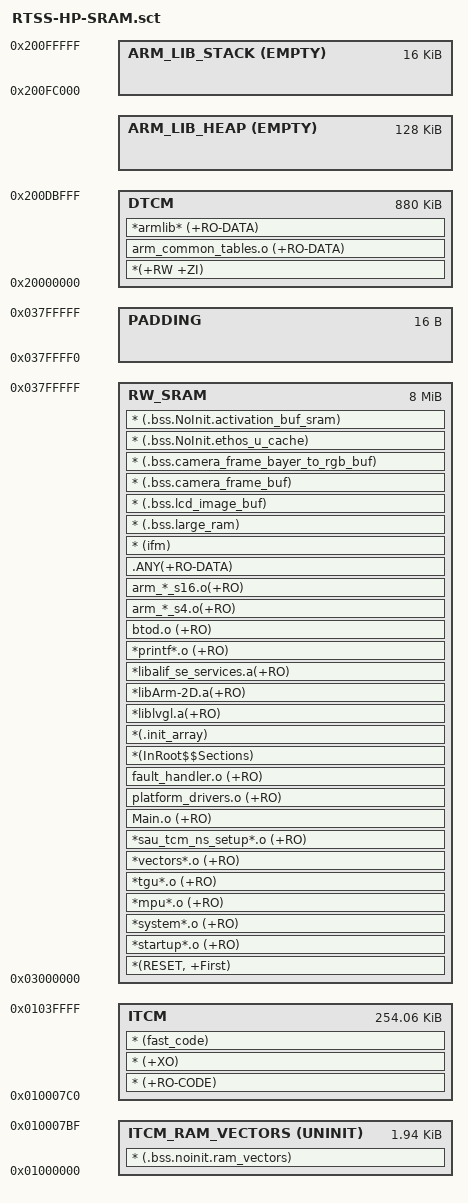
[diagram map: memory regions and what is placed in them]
#! armclang -E --target=arm-arm-none-eabi -mcpu=cortex-m55 -xc
; command above MUST be in first line (no comment above!)

;/* Copyright (C) 2022 Alif Semiconductor - All Rights Reserved.
; * Use, distribution and modification of this code is permitted under the
; * terms stated in the Alif Semiconductor Software License Agreement
; *
; * You should have received a copy of the Alif Semiconductor Software
; * License Agreement with this file. If not, please write to:
; * contact@alifsemi.com, or visit: https://alifsemi.com/license
; *
; */

/*On chip RAM Regions */
#define SRAM_BASE                 0x03000000
#define SRAM_SIZE                 0x00800000		/* 8M */
/* On Chip NVM */
#define MRAM_BASE                 0x80000000
#define MRAM_SIZE                 0x00580000		/* 5.5M */

/*--------------------- ITCM Configuration ----------------------------------*/
/* SRAM2 is mapped as ITCM */
#define ITCM_BASE                 0x01000000
#define ITCM_SIZE                 0x00040000        /* 256K */

/*--------------------- DTCM Configuration ---------------------------*/
/* SRAM3 is mapped as DTCM */
#define DTCM_BASE                 0x20000000
#define DTCM_SIZE                 0x00100000        /* 1M */

#define __VECTORS_SIZE  (496 * 4)
#define __STACK_SIZE    0x00004000
#define __HEAP_SIZE     0x00020000

;----------------------------------------------------------------------------
;   User Stack & Heap boundary definition
;----------------------------------------------------------------------------
#define __STACK_TOP     (DTCM_BASE + DTCM_SIZE)       /* starts at end of RAM */
#define __HEAP_BASE     (AlignExpr(+0, 8))            /* starts after RW_RAM section, 8 byte aligned */

;----------------------------------------------------------------------------
;  Scatter File Definitions definition
;----------------------------------------------------------------------------
#define __RO_BASE       SRAM_BASE
#define __RO_SIZE       SRAM_SIZE

#define __RW_BASE       DTCM_BASE
#define __RW_SIZE      (DTCM_SIZE - __STACK_SIZE - __HEAP_SIZE)


LR_SRAM __RO_BASE __RO_SIZE  {                       ; load region size_region
  RW_SRAM __RO_BASE __RO_SIZE {                      ; load address = execution address
   ; SRAM has start-up code, LVGL read-only, and most constant data
   *(RESET, +First)
   *startup*.o (+RO)
   *system*.o (+RO)
   *mpu*.o (+RO)
   *tgu*.o (+RO)
   *vectors*.o (+RO)
   *sau_tcm_ns_setup*.o (+RO)
   Main.o (+RO)
   platform_drivers.o (+RO)
   fault_handler.o (+RO)
   *(InRoot$$Sections)
   *(.init_array)
   *liblvgl.a(+RO)
   *libArm-2D.a(+RO)
   *libalif_se_services.a(+RO)
   *printf*.o (+RO)
   btod.o (+RO)
   arm_*_s4.o(+RO)
   arm_*_s16.o(+RO)
   .ANY(+RO-DATA)

      * (ifm)                                ; Baked-in inputs
      * (.bss.large_ram)                     ; Large LVGL buffers
      * (.bss.lcd_image_buf)
      * (.bss.camera_frame_buf)              ; Camera Frame Buffer
      * (.bss.camera_frame_bayer_to_rgb_buf) ; (Optional) Camera Frame Buffer for Bayer to RGB Convertion.
      ; Cache area (if used)
      * (.bss.NoInit.ethos_u_cache)
      ; activation buffers a.k.a tensor arena when memory mode sram only or shared sram
      * (.bss.NoInit.activation_buf_sram)
  }

  ITCM_RAM_VECTORS ITCM_BASE UNINIT ALIGN 2048 __VECTORS_SIZE {
      * (.bss.noinit.ram_vectors)
  }

  ITCM ITCM_BASE+__VECTORS_SIZE ITCM_SIZE-__VECTORS_SIZE {  ; --------------------------------
      ; ITCM has non-startup code, except for non-fast LVGL, and RAM vectors
      * (+RO-CODE)
      * (+XO)
      * (fast_code)
  }

  ;-----------------------------------------------------
  ; R/W region - remaining part of the DTCM region
  ; Other parts of this region used up by stack + heap.
  ;-----------------------------------------------------
  DTCM __RW_BASE __RW_SIZE  {  ; RW data in DTCM
      ; DTCM has CMSIS-DSP tables, ARM library const data (eg maths tables)
      ; and all read-write data, except image and NPU buffers
      *(+RW +ZI)
      arm_common_tables.o (+RO-DATA)
      *armlib* (+RO-DATA)
  }

  ARM_LIB_HEAP  __HEAP_BASE EMPTY  __HEAP_SIZE  {  }
  ARM_LIB_STACK __STACK_TOP EMPTY -__STACK_SIZE {  }

  PADDING SRAM_BASE+SRAM_SIZE-16 ALIGN 16 FILL 0 16  {  }
}
